# PT32G031xx register map
File version: 0.4
Registers are 32-bit, read-write, reset 0x0 unless marked. A register's access mark holds for its fields unless they carry their own. Offsets are from the block's base; [hi:lo] are bit positions; {n}, {i} and the like mark numbered series; 'fields as' and 'values as' point back to an identical list.

## TIM1 — Advanced timer
Base 0x40012C00
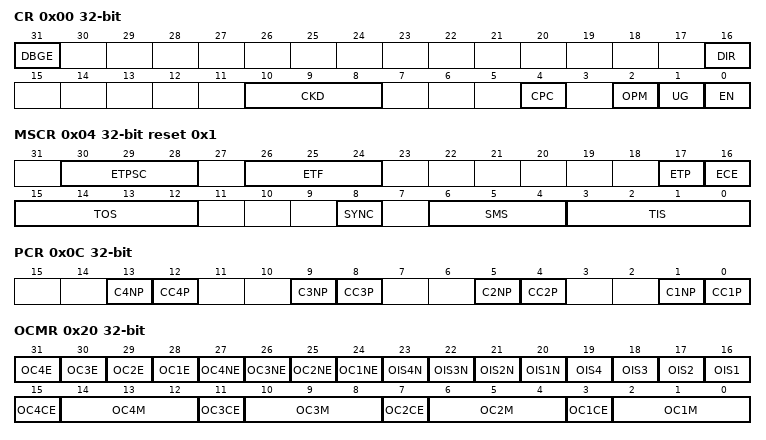
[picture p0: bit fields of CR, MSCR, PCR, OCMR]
0x00 CR access per field — Control Register
  [31] DBGE rw — TIM debug
  [16] DIR rw — Direction
  [10:8] CKD rw — Sampling clock division
  [4] CPC rw — Comparepre loaded control
  [2] OPM rw — One-pulse mode
  [1] UG wo — Update generation
  [0] EN rw — TIM enable
0x04 MSCR reset 0x1 — Master And Slave Mode Control Register
  [30:28] ETPSC — External trigger prescaler
  [26:24] ETF — External trigger filter
  [17] ETP — External trigger polarity
  [16] ECE — External clock enable
  [15:12] TOS — Trigger output selection
  [8] SYNC — TIM synchronization enable
  [6:4] SMS — Slave mode selection
  [3:0] TIS — Trigger input selection
0x0C PCR — Polarity Control Register
  [4n-3] C{n}NP (n=1..4) — Compare {n} complementary output polarity
  [4n-4] CC{n}P (n=1..4) — Capture/Compare {n} output polarity
0x20 OCMR — Output Compare Mode Register
  [n+27] OC{n}E (n=1..4) — Compare output {n} output enable
  [n+23] OC{n}NE (n=1..4) — Compare output {n} complementary output enable
  [n+19] OIS{n}N (n=1..4) — Output Idle state {n} complementary
  [n+15] OIS{n} (n=1..4) — Output Idle state {n}
  [4n-1] OC{n}CE (n=1..4) — output compare {n} clear enable
  [4n-2:4n-4] OC{n}M (n=1..4) — output compare {n} mode
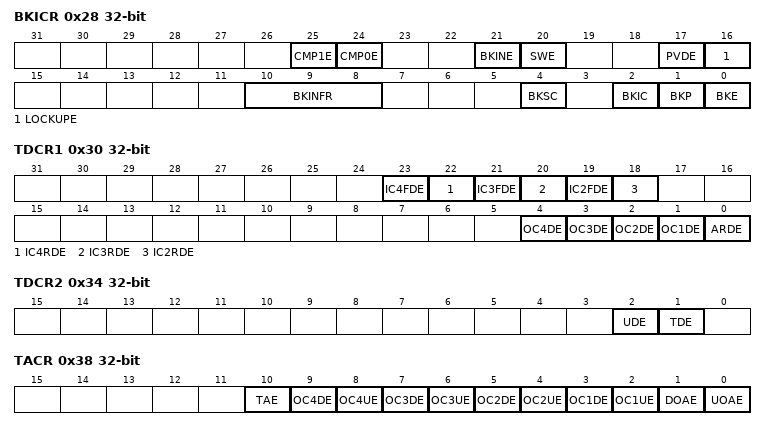
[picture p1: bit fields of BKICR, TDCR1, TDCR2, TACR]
0x28 BKICR — Break Input Control Register
  [25] CMP1E — CMP1 Break input enable
  [24] CMP0E — CMP0 Break input enable
  [21] BKINE — BKIN Break input enable
  [20] SWE — SW Break input enable
  [17] PVDE — PVD break input enable
  [16] LOCKUPE — LOCKUP break input enable
  [10:8] BKINFR — BKIN Input filter
  [4] BKSC — Break software control enable
  [2] BKIC — break input control
  [1] BKP — Break polarity
  [0] BKE — Break enable
0x2C DTCR — Dead Time Control Register
  [11:0] DT — Dead-time value
0x30 TDCR1 — Trigger DMA Control Register 1
  [23] IC4FDE — input capture 4 falling edge DMA request enable
  [22] IC4RDE — input capture 4 rising edge DMA request enable
  [21] IC3FDE — input capture 3 falling edge DMA request enable
  [20] IC3RDE — input capture 3 rising edge DMA request enable
  [19] IC2FDE — input capture 2 falling edge DMA request enable
  [18] IC2RDE — input capture 2 rising edge DMA request enable
  [n] OC{n}DE (n=1..4) — output compare {n} DMA request enable
  [0] ARDE — auto reload DMA request enable
0x34 TDCR2 — Trigger DMA Control Register 2
  [2] UDE — update DMA request enable
  [1] TDE — trigger DMA request enable
0x38 TACR — Regular Trigger ADC Control Register
  [10] TAE — TEV trigger ADC enable
  [2n+1] OC{n}DE (n=1..4) — OC{n}D trigger ADC enable
  [2n] OC{n}UE (n=1..4) — OC{n}U trigger ADC enable
  [1] DOAE — DownOVF trigger ADC enable
  [0] UOAE — UpOVF trigger ADC enable
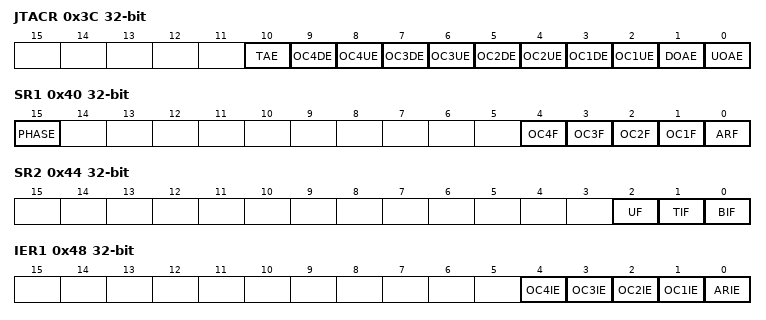
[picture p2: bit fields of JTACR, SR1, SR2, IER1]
0x3C JTACR — Injected Trigger ADC Control Register
  fields as TACR
0x40 SR1 access per field — Status Register 1
  [15] PHASE ro — Phase shift function flag
  [n] OC{n}F rw (n=1..4) — Output compare {n} flag
  [0] ARF rw — Auto reload flag
0x44 SR2 — Status Register 2
  [2] UF — update flag
  [1] TIF — Trigger input flag
  [0] BIF — Break input flag
0x48 IER1 — Interrupt Enable Register 1
  [n] OC{n}IE (n=1..4) — output compare {n} interrupt enable
  [0] ARIE — Auto reload interrupt enable
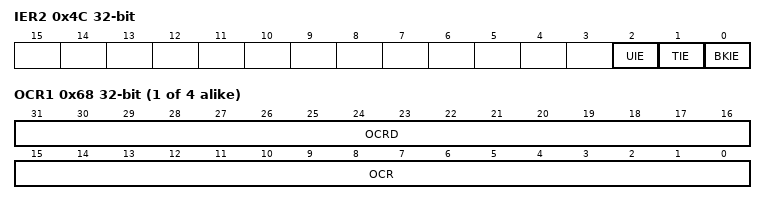
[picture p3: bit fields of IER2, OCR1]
0x4C IER2 — Interrupt Enable Register 2
  [2] UIE — Update interrupt enable
  [1] TIE — Trigger interrupt enable
  [0] BKIE — Break interrupt enable
0x50 ITARR — Interrupt Auto Reload Register
  [3:0] ITARR — TIM interrupt auto reload
0x54 ITCNTR ro — Interrupt Counter Register
  [3:0] ITCNT — TIM interrupt counter value
0x58 PSCR — Prescaler Register
  [15:0] PSC — Prescaler value
0x60 CNTR — Counter Register
  [15:0] CNT — Counter value
0x64 ARR — Auto Reload Register
  [15:0] ARR — Auto reload value
{0x64+4i} OCR{i} (i=1..4) — Output Compare Register {i}
  [31:16] OCRD — output compare value when counting down
  [15:0] OCR — output compare value
